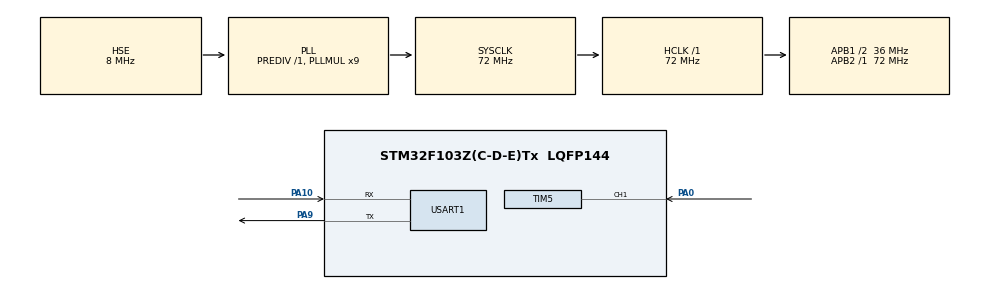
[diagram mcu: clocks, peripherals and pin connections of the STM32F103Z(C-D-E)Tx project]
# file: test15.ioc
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Mcu.Family=STM32F1
Mcu.Name=STM32F103Z(C-D-E)Tx
Mcu.Package=LQFP144
NVIC.PriorityGroup=NVIC_PRIORITYGROUP_4
NVIC.TIM5_IRQn=true\:0\:0\:false\:false\:true\:true\:true\:true
NVIC.USART1_IRQn=true\:0\:0\:false\:false\:true\:true\:true\:true
OSC_IN.Mode=HSE-External-Oscillator
OSC_IN.Signal=RCC_OSC_IN
OSC_OUT.Mode=HSE-External-Oscillator
OSC_OUT.Signal=RCC_OSC_OUT
PA0-WKUP.GPIO_PuPd=GPIO_PULLDOWN
PA0-WKUP.Signal=S_TIM5_CH1
PA10.Mode=Asynchronous
PA10.Signal=USART1_RX
PA13.Mode=Serial_Wire
PA13.Signal=SYS_JTMS-SWDIO
PA14.Mode=Serial_Wire
PA14.Signal=SYS_JTCK-SWCLK
PA9.Mode=Asynchronous
PA9.Signal=USART1_TX
ProjectManager.HeapSize=0x200
ProjectManager.StackSize=0x400
ProjectManager.TargetToolchain=MDK-ARM V5.32
RCC.AHBFreq_Value=72000000
RCC.APB1CLKDivider=RCC_HCLK_DIV2
RCC.APB1Freq_Value=36000000
RCC.APB1TimFreq_Value=72000000
RCC.APB2Freq_Value=72000000
RCC.APB2TimFreq_Value=72000000
RCC.HCLKFreq_Value=72000000
RCC.PLLMUL=RCC_PLL_MUL9
RCC.PLLSourceVirtual=RCC_PLLSOURCE_HSE
RCC.SYSCLKFreq_VALUE=72000000
RCC.SYSCLKSource=RCC_SYSCLKSOURCE_PLLCLK
RCC.USBFreq_Value=72000000
SH.S_TIM5_CH1.0=TIM5_CH1,Input_Capture1_from_TI1
TIM5.Channel-Input_Capture1_from_TI1=TIM_CHANNEL_1
TIM5.Period=500-1
TIM5.Prescaler=72-1
USART1.VirtualMode=VM_ASYNC
VP_TIM5_VS_ClockSourceINT.Mode=Internal
board=custom

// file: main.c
/* USER CODE BEGIN Header */
/**
 ******************************************************************************
 * @file           : main.c
 * @brief          : Main program body
 ******************************************************************************
 * @attention
 *
 * Copyright (c) 2023 STMicroelectronics.
 * All rights reserved.
 *
 * This software is licensed under terms that can be found in the LICENSE file
 * in the root directory of this software component.
 * If no LICENSE file comes with this software, it is provided AS-IS.
 *
 ******************************************************************************
 */
/* USER CODE END Header */
#include "main.h"
#include "tim.h"
#include "usart.h"
#include "gpio.h"

/* USER CODE BEGIN Includes */
#include <stdio.h>
#include <string.h>
/* USER CODE END Includes */

/* USER CODE BEGIN PD */
uint8_t TIM5CH1_CAPTURE_STA = 0; // 输入捕获状态
uint16_t TIM5CH1_CAPTURE_VAL;    // 输入捕获值(TIM5 是 16 位)
/* USER CODE END PD */

/* USER CODE BEGIN PV */
// 定时器更新中断（计数溢出）中断处理回调函数，
// 该函数在 HAL_TIM_IRQHandler 中会被调用
void HAL_TIM_PeriodElapsedCallback(TIM_HandleTypeDef *htim)
// 更新中断（溢出）发生时执行
{
  if ((TIM5CH1_CAPTURE_STA & 0X80) == 0) // 还未成功捕获
  {
    if (TIM5CH1_CAPTURE_STA & 0X40) // 已经捕获到高电平了
    {
      if ((TIM5CH1_CAPTURE_STA & 0X3F) == 0X3F) // 高电平太长了
      {
        TIM5CH1_CAPTURE_STA |= 0X80; // 标记成功捕获了一次
        TIM5CH1_CAPTURE_VAL = 0XFFFF;
      }
      else
        TIM5CH1_CAPTURE_STA++;
    }
  }
}

void HAL_TIM_IC_CaptureCallback(TIM_HandleTypeDef *htim) // 捕获中断发生时执行
{
  if ((TIM5CH1_CAPTURE_STA & 0X80) == 0) // 还未成功捕获
  {
    if (TIM5CH1_CAPTURE_STA & 0X40) // 捕获到一个下降沿
    {
      TIM5CH1_CAPTURE_STA |= 0X80;                                            // 标记成功捕获到一次高电平脉宽
      TIM5CH1_CAPTURE_VAL = HAL_TIM_ReadCapturedValue(&htim5, TIM_CHANNEL_1); // 获取当前的捕获值.
      TIM_RESET_CAPTUREPOLARITY(&htim5, TIM_CHANNEL_1);
      // 一定要先清除原来的设置！！
      TIM_SET_CAPTUREPOLARITY(&htim5, TIM_CHANNEL_1,
                              TIM_ICPOLARITY_RISING); // 配置 TIM5 通道 1 上升沿捕获
    }
    else // 还未开始,第一次捕获上升沿
    {
      TIM5CH1_CAPTURE_STA = 0; // 清空
      TIM5CH1_CAPTURE_VAL = 0;
      TIM5CH1_CAPTURE_STA |= 0X40; // 标记捕获到了上升沿
      __HAL_TIM_DISABLE(&htim5);   // 关闭定时器 5
      __HAL_TIM_SET_COUNTER(&htim5, 0);
      TIM_RESET_CAPTUREPOLARITY(&htim5, TIM_CHANNEL_1);
      // 一定要先清除原来的设置！！
      TIM_SET_CAPTUREPOLARITY(&htim5, TIM_CHANNEL_1,
                              TIM_ICPOLARITY_FALLING); // 定时器 5 通道 1 设置为下降沿捕获
      __HAL_TIM_ENABLE(&htim5);                        // 使能定时器 5
    }
  }
}

/* USER CODE END PV */

void SystemClock_Config(void);

int main(void)
{

  /* MCU Configuration--------------------------------------------------------*/

  /* Reset of all peripherals, Initializes the Flash interface and the Systick. */
  HAL_Init();

  /* Configure the system clock */
  SystemClock_Config();

  /* Initialize all configured peripherals */
  MX_GPIO_Init();
  MX_TIM5_Init();
  MX_USART1_UART_Init();
  /* USER CODE BEGIN 2 */
  HAL_TIM_IC_Start_IT(&htim5, TIM_CHANNEL_1);
  long long temp = 0;
  /* USER CODE END 2 */

  /* Infinite loop */
  /* USER CODE BEGIN WHILE */
  while (1)
  {
    if (TIM5CH1_CAPTURE_STA & 0X80) // 成功捕获到了一次高电平
    {
      temp = TIM5CH1_CAPTURE_STA & 0X3F;
      temp *= 65536;                    // 溢出时间总和
      temp += TIM5CH1_CAPTURE_VAL;      // 得到总的高电平时间
      char send_data[20];//存放发送数据的数组
      sprintf(send_data, "HIGH:%lld us\r\n", temp); // 打印总的高点平时间
      HAL_UART_Transmit(&huart1, (uint8_t *)send_data, strlen(send_data), 50);
      TIM5CH1_CAPTURE_STA = 0;          // 开启下一次捕获
    }

    /* USER CODE END WHILE */

  }
}

void SystemClock_Config(void)
{
  RCC_OscInitTypeDef RCC_OscInitStruct = {0};
  RCC_ClkInitTypeDef RCC_ClkInitStruct = {0};

  /** Initializes the RCC Oscillators according to the specified parameters
   * in the RCC_OscInitTypeDef structure.
   */
  RCC_OscInitStruct.OscillatorType = RCC_OSCILLATORTYPE_HSE;
  RCC_OscInitStruct.HSEState = RCC_HSE_ON;
  RCC_OscInitStruct.HSEPredivValue = RCC_HSE_PREDIV_DIV1;
  RCC_OscInitStruct.HSIState = RCC_HSI_ON;
  RCC_OscInitStruct.PLL.PLLState = RCC_PLL_ON;
  RCC_OscInitStruct.PLL.PLLSource = RCC_PLLSOURCE_HSE;
  RCC_OscInitStruct.PLL.PLLMUL = RCC_PLL_MUL9;
  if (HAL_RCC_OscConfig(&RCC_OscInitStruct) != HAL_OK)
  {
    Error_Handler();
  }

  /** Initializes the CPU, AHB and APB buses clocks
   */
  RCC_ClkInitStruct.ClockType = RCC_CLOCKTYPE_HCLK | RCC_CLOCKTYPE_SYSCLK | RCC_CLOCKTYPE_PCLK1 | RCC_CLOCKTYPE_PCLK2;
  RCC_ClkInitStruct.SYSCLKSource = RCC_SYSCLKSOURCE_PLLCLK;
  RCC_ClkInitStruct.AHBCLKDivider = RCC_SYSCLK_DIV1;
  RCC_ClkInitStruct.APB1CLKDivider = RCC_HCLK_DIV2;
  RCC_ClkInitStruct.APB2CLKDivider = RCC_HCLK_DIV1;

  if (HAL_RCC_ClockConfig(&RCC_ClkInitStruct, FLASH_LATENCY_2) != HAL_OK)
  {
    Error_Handler();
  }
}

void Error_Handler(void)
{
  __disable_irq();
  while (1)
  {
  }
}
